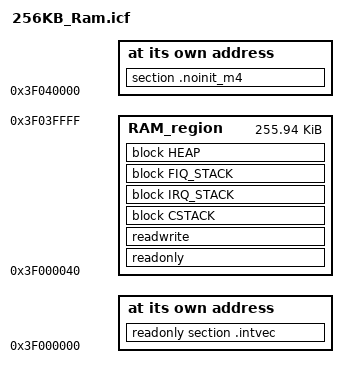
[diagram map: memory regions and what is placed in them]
/*###ICF### Section handled by ICF editor, don't touch! ****/
/*-Editor annotation file-*/
/* IcfEditorFile="$TOOLKIT_DIR$\config\ide\IcfEditor\a_v1_0.xml" */
/*-Specials-*/
define symbol __ICFEDIT_intvec_start__ = 0x3f000000;
/*-Memory Regions-*/
define symbol __ICFEDIT_region_ROM_start__   = 0x0;
define symbol __ICFEDIT_region_ROM_end__     = 0x0;
define symbol __ICFEDIT_region_RAM_start__   = 0x3f000040;
define symbol __ICFEDIT_region_RAM_end__     = 0x3f03ffff;
/*-Sizes-*/
define symbol __ICFEDIT_size_cstack__   = 0x1000;
define symbol __ICFEDIT_size_svcstack__ = 0x40;
define symbol __ICFEDIT_size_irqstack__ = 0x300;
define symbol __ICFEDIT_size_fiqstack__ = 0x40;
define symbol __ICFEDIT_size_undstack__ = 0x40;
define symbol __ICFEDIT_size_abtstack__ = 0x40;
define symbol __ICFEDIT_size_heap__     = 0x2000;
/**** End of ICF editor section. ###ICF###*/

define exported symbol __intvec_start = __ICFEDIT_intvec_start__;

define symbol __code_start_m4__ = 0x3f040000;

define memory mem with size = 4G;
define region ROM_region   = mem:[from __ICFEDIT_region_ROM_start__   to __ICFEDIT_region_ROM_end__];
define region RAM_region   = mem:[from __ICFEDIT_region_RAM_start__   to __ICFEDIT_region_RAM_end__];

define block CSTACK    with alignment = 8, size = __ICFEDIT_size_cstack__   { };
define block IRQ_STACK with alignment = 8, size = __ICFEDIT_size_irqstack__ { };
define block FIQ_STACK with alignment = 8, size = __ICFEDIT_size_fiqstack__ { };
define block HEAP      with alignment = 8, size = __ICFEDIT_size_heap__     { };

do not initialize   { section .noinit };

place at address mem:__ICFEDIT_intvec_start__ { readonly section .intvec };

place in RAM_region   { readonly};

place in RAM_region   { readwrite,
                        block CSTACK, block IRQ_STACK, block FIQ_STACK, block HEAP };

place at address mem:__code_start_m4__ { section .noinit_m4 };
